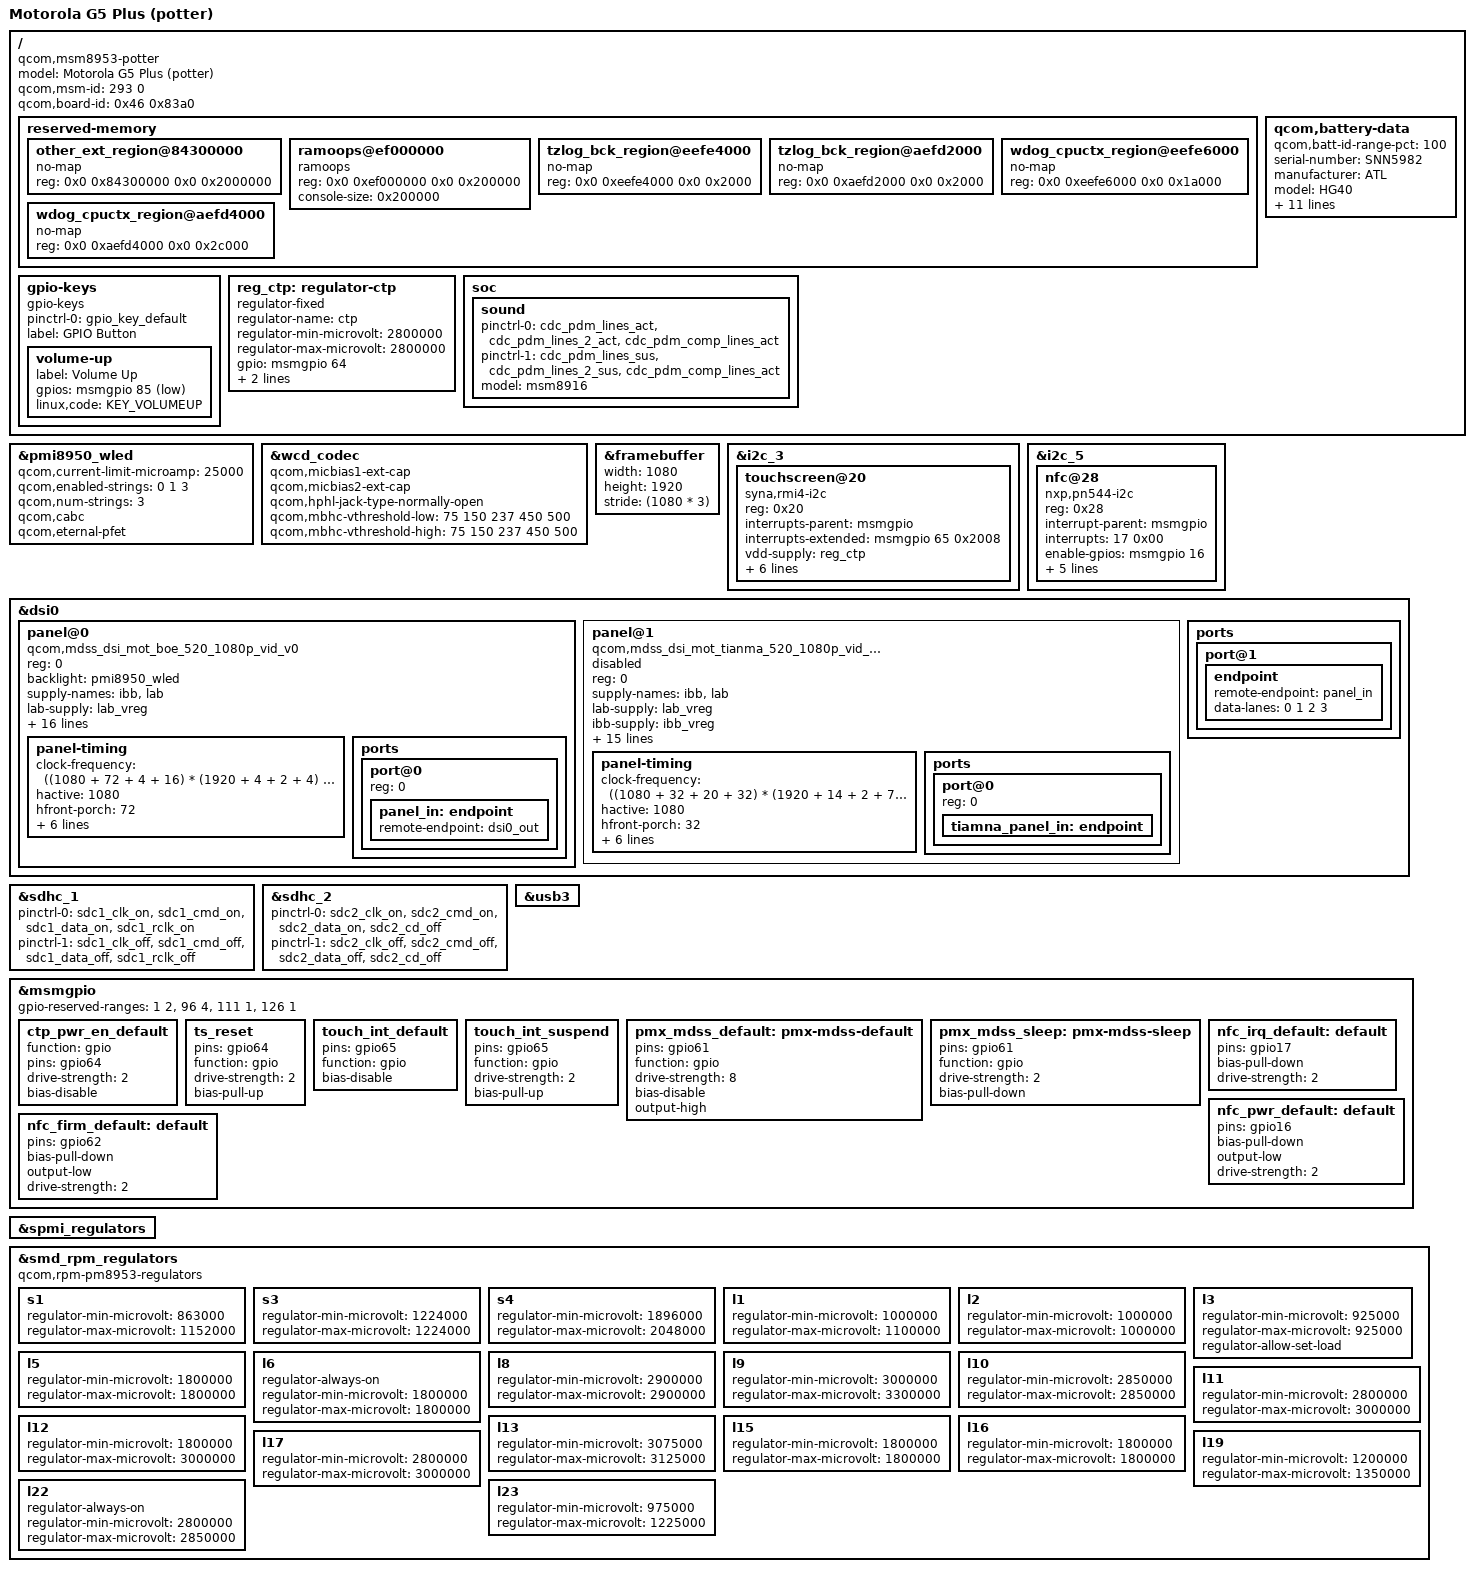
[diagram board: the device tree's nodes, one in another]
/* Copyright (c) 2017,2020 The Linux Foundation. All rights reserved.
 *
 * This program is free software; you can redistribute it and/or modify
 * it under the terms of the GNU General Public License version 2 and
 * only version 2 as published by the Free Software Foundation.
 *
 * This program is distributed in the hope that it will be useful,
 * but WITHOUT ANY WARRANTY; without even the implied warranty of
 * MERCHANTABILITY or FITNESS FOR A PARTICULAR PURPOSE.  See the
 * GNU General Public License for more details.
 */
/dts-v1/;

#include "msm8953.dtsi"
#include "pm8953.dtsi"
#include "pmi8950.dtsi"
#include <dt-bindings/gpio/gpio.h>
#include <dt-bindings/display/mipi-dsi-generic.h>

/ {
	model = "Motorola G5 Plus (potter)";
	compatible = "qcom,msm8953-potter", "qcom,msm8953-moto", "qcom,msm8953";
	qcom,msm-id = <293 0>;
	qcom,board-id = <0x46 0x83a0>;

	reserved-memory {
		/delete-node/other_ext_region@85b00000;

		other_ext_region@84300000 {
			no-map;
			reg = <0x0 0x84300000 0x0 0x2000000>;
		};

		ramoops@ef000000 {
			compatible = "ramoops";
			reg = <0x0 0xef000000 0x0 0x200000>;
			console-size = <0x200000>;
		};

		tzlog_bck_region@eefe4000 {
			no-map;
			reg = <0x0 0xeefe4000 0x0 0x2000>;
		};

		tzlog_bck_region@aefd2000 {
			no-map;
			reg = <0x0 0xaefd2000 0x0 0x2000>;
		};

		wdog_cpuctx_region@eefe6000 {
			no-map;
			reg = <0x0 0xeefe6000 0x0 0x1a000>;
		};

		wdog_cpuctx_region@aefd4000 {
			no-map;
			reg = <0x0 0xaefd4000 0x0 0x2c000>;
		};

	};

	gpio-keys {
		compatible = "gpio-keys";

		pinctrl-names = "default";
		pinctrl-0 = <&gpio_key_default>;

		label = "GPIO Button";

		volume-up {
			label = "Volume Up";
			gpios = <&msmgpio 85 GPIO_ACTIVE_LOW>;
			linux,code = <KEY_VOLUMEUP>;
		};
	};

	qcom,battery-data {
		qcom,batt-id-range-pct = <100>;
		serial-number = "SNN5982";
		manufacturer = "ATL";
		model = "HG40";

		qcom,max-voltage-uv = <4400000>;
		qcom,batt-id-kohm = <0>;
		qcom,battery-beta = <0>;
		qcom,battery-type = "HG40-ATL-3000mah";
		qcom,chg-rslow-comp-c1 = <3073614>;
		qcom,chg-rslow-comp-c2 = <3981400>;
		qcom,chg-rs-to-rslow = <1280731>;
		qcom,chg-rslow-comp-thr = <157>;
		qcom,thermal-coefficients = [69 86 5d 4b 62 35];
		qcom,fg-profile-data = [ E0 83 C3 7C
					 0F 81 36 77
					 65 83 4C 74
					 5C 89 67 94
					 3A 82 6D 99
					 54 BC AA C8
					 56 10 02 88
					 A7 7D A8 81
					 1F 7C 54 83
					 34 6A B6 78
					 21 86 4E 82
					 B5 99 08 BD
					 07 CA 59 0D
					 DE 0B 7F 59
					 14 70 B2 FD
					 E0 35 52 3E
					 FD 16 00 00
					 17 46 56 23
					 5F 28 00 00
					 00 00 00 00
					 00 00 00 00
					 EC 70 41 70
					 31 71 E9 83
					 EF 6E 25 5A
					 34 5A 39 7A
					 A8 6E 4D 5B
					 28 7F 6B 96
					 17 A1 62 44
					 64 A0 71 0C
					 28 00 FF 36
					 F0 11 30 03
					 00 00 00 0C ];
	};

	reg_ctp: regulator-ctp {
		compatible = "regulator-fixed";
		regulator-name = "ctp";

		regulator-min-microvolt = <2800000>;
		regulator-max-microvolt = <2800000>;

		gpio = <&msmgpio 64 GPIO_ACTIVE_HIGH>;
		enable-active-high;

		pinctrl-names = "default";
		pinctrl-0 = <&ctp_pwr_en_default>;
	};

	soc {
		sound {
			status = "okay";

			pinctrl-names = "default", "sleep";
			pinctrl-0 = <&cdc_pdm_lines_act &cdc_pdm_lines_2_act &cdc_pdm_comp_lines_act>;
			pinctrl-1 = <&cdc_pdm_lines_sus &cdc_pdm_lines_2_sus &cdc_pdm_comp_lines_act>;

			model = "msm8916";
		};
	};
};

&pmi8950_wled {
	status = "okay";

	/* Don't copy-paste! See pmi8950.dtsi */

	qcom,current-limit-microamp = <25000>;
	qcom,enabled-strings = <0 1 3>;
	qcom,num-strings = <3>;

	qcom,cabc;
	qcom,eternal-pfet;
};

&wcd_codec {
	qcom,micbias1-ext-cap;
	qcom,micbias2-ext-cap;
	qcom,hphl-jack-type-normally-open;
	qcom,mbhc-vthreshold-low = <75 150 237 450 500>;
	qcom,mbhc-vthreshold-high = <75 150 237 450 500>;
};

&framebuffer {
	status = "okay";

	width = <1080>;
	height = <1920>;
	stride = <(1080 * 3)>;
};

&i2c_3 {
	status = "okay";

	touchscreen@20 {
		reg = <0x20>;
		compatible = "syna,rmi4-i2c";
		interrupts-parent = <&msmgpio>;
		interrupts-extended = <&msmgpio 65 0x2008>;

		#address-cells = <1>;
		#size-cells = <0>;

		vdd-supply = <&reg_ctp>;
		vio-supply = <&pm8953_l22>;
		gpios = <&msmgpio 65 0x2008>,
			<&msmgpio 64 GPIO_ACTIVE_HIGH>;

		pinctrl-names = "init", "suspend";
		pinctrl-0 = <&ts_reset &touch_int_default>;
		pinctrl-1 = <&ts_reset &touch_int_suspend>;
		syna,reset-delay-ms = <200>;
		syna,startup-delay-ms = <500>;
	};
};

&i2c_5 {
	status = "okay";

	nfc@28 {
		compatible = "nxp,pn544-i2c";
		reg = <0x28>;
		interrupt-parent = <&msmgpio>;
		interrupts = <17 0x00>;

		enable-gpios = <&msmgpio 16 GPIO_ACTIVE_HIGH>; /* EN */
		firmware-gpios = <&msmgpio 62 GPIO_ACTIVE_HIGH>; /* Firmware */

		nxp,pnxx-discharge-delay = <100>;
		nxp,pnxx-ven-inv-polarity = <0x00>;

		pinctrl-names = "default";
		pinctrl-0 = <&nfc_irq_default &nfc_pwr_default &nfc_firm_default>;
	};
};

&dsi0 {
	panel@0 {
		compatible = "qcom,mdss_dsi_mot_boe_520_1080p_vid_v0", "panel-mipi-dsi-generic";
		reg = <0>;

		backlight = <&pmi8950_wled>;

		supply-names = "ibb", "lab";
		lab-supply = <&lab_vreg>;
		ibb-supply = <&ibb_vreg>;

		reset-gpios = <&msmgpio 61 GPIO_ACTIVE_LOW>;
		reset-sequence = <0 5>, <1 5>, <0 5>, <1 5>, <0 20>;

		pinctrl-names = "default", "sleep";
		pinctrl-0 = <&pmx_mdss_default>;
		pinctrl-1 = <&pmx_mdss_sleep>;

		dsi-on-commands = MIPI_CMD_DCS_WRITE(2, 0xff 0xee),
		                  MIPI_CMD_DCS_WRITE(2, 0x18 0x40),
		                  MIPI_CMD_DELAY_MS(10),
		                  MIPI_CMD_DCS_WRITE(2, 0x18 0x00),
		                  MIPI_CMD_DELAY_MS(20),
		                  MIPI_CMD_DCS_WRITE(2, 0xff 0x01),
		                  MIPI_CMD_DCS_WRITE(2, 0xfb 0x01),
		                  MIPI_CMD_DCS_WRITE(2, 0x60 0x0f),
		                  MIPI_CMD_DCS_WRITE(2, 0x6d 0x33),
		                  MIPI_CMD_DCS_WRITE(2, 0x58 0x82),
		                  MIPI_CMD_DCS_WRITE(2, 0x59 0x00),
		                  MIPI_CMD_DCS_WRITE(2, 0x5a 0x02),
		                  MIPI_CMD_DCS_WRITE(2, 0x5b 0x00),
		                  MIPI_CMD_DCS_WRITE(2, 0x5c 0x82),
		                  MIPI_CMD_DCS_WRITE(2, 0x5d 0x80),
		                  MIPI_CMD_DCS_WRITE(2, MIPI_CMD_DCS_SET_CABC_MIN_BRIGHTNESS 0x02),
		                  MIPI_CMD_DCS_WRITE(2, 0x5f 0x00),
		                  MIPI_CMD_DCS_WRITE(2, 0x1b 0x1b),
		                  MIPI_CMD_DCS_WRITE(2, 0x1c 0xf7),
		                  MIPI_CMD_DCS_WRITE(2, 0x66 0x01),
		                  MIPI_CMD_DCS_WRITE(2, 0xff 0x05),
		                  MIPI_CMD_DCS_WRITE(2, 0xfb 0x01),
		                  MIPI_CMD_DCS_WRITE(2, 0xa6 0x04),
		                  MIPI_CMD_DCS_WRITE(2, 0xff 0xff),
		                  MIPI_CMD_DCS_WRITE(2, 0xfb 0x01),
		                  MIPI_CMD_DCS_WRITE(2, 0x4f 0x03),
		                  MIPI_CMD_DCS_WRITE(2, 0xff 0x05),
		                  MIPI_CMD_DCS_WRITE(2, 0xfb 0x01),
		                  MIPI_CMD_DCS_WRITE(2, 0x86 0x1b),
		                  MIPI_CMD_DCS_WRITE(2, 0x87 0x39),
		                  MIPI_CMD_DCS_WRITE(2, 0x88 0x1b),
		                  MIPI_CMD_DCS_WRITE(2, 0x89 0x39),
		                  MIPI_CMD_DCS_WRITE(2, 0x8c 0x01),
		                  MIPI_CMD_DCS_WRITE(2, 0xb5 0x20),
		                  MIPI_CMD_DCS_WRITE(2, 0xff 0x00),
		                  MIPI_CMD_DCS_WRITE(2, 0xfb 0x01),
		                  MIPI_CMD_DCS_WRITE(2, MIPI_CMD_DCS_SET_DISPLAY_BRIGHTNESS 0xcc),
		                  MIPI_CMD_DCS_WRITE(2, MIPI_CMD_DCS_SET_CABC_MIN_BRIGHTNESS 0x00),
		                  MIPI_CMD_DCS_WRITE(2, MIPI_CMD_DCS_WRITE_CONTROL_DISPLAY 0x2c),
		                  MIPI_CMD_DCS_WRITE(2, MIPI_CMD_DCS_WRITE_POWER_SAVE 0x01),
		                  MIPI_CMD_DCS_WRITE(2, 0x34 0x00),
		                  MIPI_CMD_DCS_WRITE(2, 0xd3 0x06),
		                  MIPI_CMD_DCS_WRITE(2, 0xd4 0x04),
		                  MIPI_CMD_DCS_WRITE(1, MIPI_CMD_DCS_EXIT_SLEEP_MODE),
		                  MIPI_CMD_DELAY_MS(120),
		                  MIPI_CMD_DCS_WRITE(2, 0xff 0x01),
		                  MIPI_CMD_DCS_WRITE(2, 0xfb 0x01),
		                  MIPI_CMD_DCS_WRITE(2, 0x0e 0xb0),
		                  MIPI_CMD_DCS_WRITE(2, 0x0f 0xa9),
		                  MIPI_CMD_DCS_WRITE(2, 0xff 0x00),
		                  MIPI_CMD_DCS_WRITE(2, 0xfb 0x01),
		                  MIPI_CMD_DCS_WRITE(1, MIPI_CMD_DCS_SET_DISPLAY_ON),
		                  MIPI_CMD_DELAY_MS(10);
		dsi-off-commands = MIPI_CMD_DCS_WRITE(1, MIPI_CMD_DCS_SET_DISPLAY_OFF),
		                   MIPI_CMD_DELAY_MS(35),
		                   MIPI_CMD_DCS_WRITE(1, MIPI_CMD_DCS_ENTER_SLEEP_MODE),
		                   MIPI_CMD_DELAY_MS(120);
		dsi-format = <MIPI_GENERIC_DSI_FMT_RGB888>;
		dsi-lanes = <4>;
		dsi-mode = <(MIPI_GENERIC_DSI_MODE_VIDEO
			    |MIPI_GENERIC_DSI_MODE_VIDEO_BURST
			    |MIPI_GENERIC_DSI_CLOCK_NON_CONTINUOUS
			    |MIPI_GENERIC_DSI_MODE_LPM)>;

		panel-refresh-rate = <60>;
		panel-width-mm = <68>;
		panel-height-mm = <121>;

		panel-timing {
			clock-frequency = <((1080 + 72 + 4 + 16) * (1920 + 4 + 2 + 4) * 60)>;

			hactive = <1080>;
			hfront-porch = <72>;
			hback-porch = <16>;
			hsync-len = <4>;

			vactive = <1920>;
			vfront-porch = <4>;
			vback-porch = <4>;
			vsync-len = <2>;
		};

		ports {
			#address-cells = <1>;
			#size-cells = <0>;

			port@0 {
				reg = <0>;
				panel_in: endpoint {
					remote-endpoint = <&dsi0_out>;
				};
			};
		};
	};

	panel@1 {
		status = "disabled";

		compatible = "qcom,mdss_dsi_mot_tianma_520_1080p_vid_v0", "panel-mipi-dsi-generic";
		reg = <0>;

		supply-names = "ibb", "lab";
		lab-supply = <&lab_vreg>;
		ibb-supply = <&ibb_vreg>;

		reset-gpios = <&msmgpio 61 GPIO_ACTIVE_LOW>;
		reset-sequence = <0 1>, <1 1>, <0 5>;

		pinctrl-names = "default", "sleep";
		pinctrl-0 = <&pmx_mdss_default>;
		pinctrl-1 = <&pmx_mdss_sleep>;

		dsi-on-commands = MIPI_CMD_DCS_WRITE(1, MIPI_CMD_DCS_EXIT_SLEEP_MODE),
		                  MIPI_CMD_DELAY_MS(120),
		                  MIPI_CMD_DCS_WRITE(2, MIPI_CMD_DCS_SET_DISPLAY_BRIGHTNESS 0xcc),
		                  MIPI_CMD_DCS_WRITE(2, MIPI_CMD_DCS_SET_CABC_MIN_BRIGHTNESS 0x00),
		                  MIPI_CMD_DCS_WRITE(2, MIPI_CMD_DCS_WRITE_CONTROL_DISPLAY 0x2c),
		                  MIPI_CMD_DCS_WRITE(2, MIPI_CMD_DCS_WRITE_POWER_SAVE 0x01),
		                  MIPI_CMD_DCS_WRITE(1, MIPI_CMD_DCS_SET_DISPLAY_ON),
		                  MIPI_CMD_DELAY_MS(10);
		dsi-off-commands = MIPI_CMD_DCS_WRITE(1, MIPI_CMD_DCS_SET_DISPLAY_OFF),
		                   MIPI_CMD_DELAY_MS(35),
		                   MIPI_CMD_DCS_WRITE(1, MIPI_CMD_DCS_ENTER_SLEEP_MODE),
		                   MIPI_CMD_DELAY_MS(120);
		dsi-format = <MIPI_GENERIC_DSI_FMT_RGB888>;
		dsi-lanes = <4>;
		dsi-mode = <(MIPI_GENERIC_DSI_MODE_VIDEO
			    |MIPI_GENERIC_DSI_MODE_VIDEO_BURST
			    |MIPI_GENERIC_DSI_CLOCK_NON_CONTINUOUS
			    |MIPI_GENERIC_DSI_MODE_LPM)>;

		panel-refresh-rate = <60>;
		panel-width-mm = <68>;
		panel-height-mm = <121>;

		panel-timing {
			clock-frequency = <((1080 + 32 + 20 + 32) * (1920 + 14 + 2 + 7) * 60)>;

			hactive = <1080>;
			hfront-porch = <32>;
			hback-porch = <32>;
			hsync-len = <20>;

			vactive = <1920>;
			vfront-porch = <14>;
			vback-porch = <7>;
			vsync-len = <2>;
		};

		ports {
			#address-cells = <1>;
			#size-cells = <0>;

			port@0 {
				reg = <0>;
				tiamna_panel_in: endpoint {
				};
			};
		};
	};

	ports {
		port@1 {
			endpoint {
				remote-endpoint = <&panel_in>;
				data-lanes = <0 1 2 3>;
			};
		};
	};
};

&sdhc_1 {
	status = "okay";

	pinctrl-names = "default", "sleep";
	pinctrl-0 = <&sdc1_clk_on &sdc1_cmd_on &sdc1_data_on  &sdc1_rclk_on>;
	pinctrl-1 = <&sdc1_clk_off &sdc1_cmd_off &sdc1_data_off &sdc1_rclk_off>;
};

&sdhc_2 {
	status = "okay";

	// cd-gpios = <&msmgpio 133 GPIO_ACTIVE_HIGH>;
	/* FIXME: triggers eject during modem initialization */

	pinctrl-names = "default", "sleep";
	pinctrl-0 = <&sdc2_clk_on &sdc2_cmd_on &sdc2_data_on &sdc2_cd_off>;
	pinctrl-1 = <&sdc2_clk_off &sdc2_cmd_off &sdc2_data_off &sdc2_cd_off>;

};

&usb3 {
	status = "okay";
};

&msmgpio {
	gpio-reserved-ranges = <1 2>, <96 4>, <111 1>, <126 1>; //NOTE: Add Fingerprint

	ctp_pwr_en_default: ctp_pwr_en_default {
		function = "gpio";
		pins = "gpio64";
		drive-strength = <2>;
		bias-disable;
	};

	ts_reset: ts_reset {
		pins = "gpio64";
		function = "gpio";
		drive-strength = <2>;
		bias-pull-up;
	};

	touch_int_default: touch_int_default {
		pins = "gpio65";
		function = "gpio";
		bias-disable;
	};

	touch_int_suspend: touch_int_suspend {
		pins = "gpio65";
		function = "gpio";
		drive-strength = <2>;
		bias-pull-up;
	};

	pmx_mdss_default: pmx-mdss-default {
		pins = "gpio61";
		function = "gpio";
		drive-strength = <8>;
		bias-disable;
		output-high;
	};

	pmx_mdss_sleep: pmx-mdss-sleep {
		pins = "gpio61";
		function = "gpio";
		drive-strength = <2>;
		bias-pull-down;
	};

	nfc_irq_default: default {
		pins = "gpio17";
		bias-pull-down;
		drive-strength = <2>;
	};

	nfc_pwr_default: default {
		pins = "gpio16";
		bias-pull-down;
		output-low;
		drive-strength = <2>;
	};

	nfc_firm_default: default {
		pins = "gpio62";
		bias-pull-down;
		output-low;
		drive-strength = <2>;
	};
};

&spmi_regulators {
	status = "okay";
};

&smd_rpm_regulators {
	compatible = "qcom,rpm-pm8953-regulators";

	s1 { // Modem
		regulator-min-microvolt = <863000>;
		regulator-max-microvolt = <1152000>;
	};
	s3 { // CSI
		regulator-min-microvolt = <1224000>;
		regulator-max-microvolt = <1224000>;
	};
	s4 { // Audio codec
		regulator-min-microvolt = <1896000>;
		regulator-max-microvolt = <2048000>;
	};
	l1 { // unused
		regulator-min-microvolt = <1000000>;
		regulator-max-microvolt = <1100000>;
	};
	l2 { // Always-on
		regulator-min-microvolt = <1000000>;
		regulator-max-microvolt = <1000000>;
	};
	l3 { // Usb, mdss phy
		regulator-min-microvolt = <925000>;
		regulator-max-microvolt = <925000>;
		regulator-allow-set-load;
	};
	l5 { // wcnss, sdhci, codec
		regulator-min-microvolt = <1800000>;
		regulator-max-microvolt = <1800000>;
	};
	l6 { // DSI
		regulator-always-on;
		regulator-min-microvolt = <1800000>;
		regulator-max-microvolt = <1800000>;
	};
	l8 { // sdhci
		regulator-min-microvolt = <2900000>;
		regulator-max-microvolt = <2900000>;
	};
	l9 { // wcnss
		regulator-min-microvolt = <3000000>;
		regulator-max-microvolt = <3300000>;
	};
	l10 { // unused
		regulator-min-microvolt = <2850000>;
		regulator-max-microvolt = <2850000>;
	};
	l11 { // sdhci
		regulator-min-microvolt = <2800000>;
		regulator-max-microvolt = <3000000>;
	};
	l12 { // sdhci,
		regulator-min-microvolt = <1800000>;
		regulator-max-microvolt = <3000000>;
	};
	l13 { // audio codec, usb phy
		regulator-min-microvolt = <3075000>;
		regulator-max-microvolt = <3125000>;
	};
	l15 { // unused
		regulator-min-microvolt = <1800000>;
		regulator-max-microvolt = <1800000>;
	};
	l16 { // unused
		regulator-min-microvolt = <1800000>;
		regulator-max-microvolt = <1800000>;
	};
	l17 { // dsi
		regulator-min-microvolt = <2800000>;
		regulator-max-microvolt = <3000000>;
	};
	l19 { // wcnss
		regulator-min-microvolt = <1200000>;
		regulator-max-microvolt = <1350000>;
	};
	l22 { // unused
		regulator-always-on;
		regulator-min-microvolt = <2800000>;
		regulator-max-microvolt = <2850000>;
	};
	l23 { // camera
		regulator-min-microvolt = <975000>;
		regulator-max-microvolt = <1225000>;
	};
};
